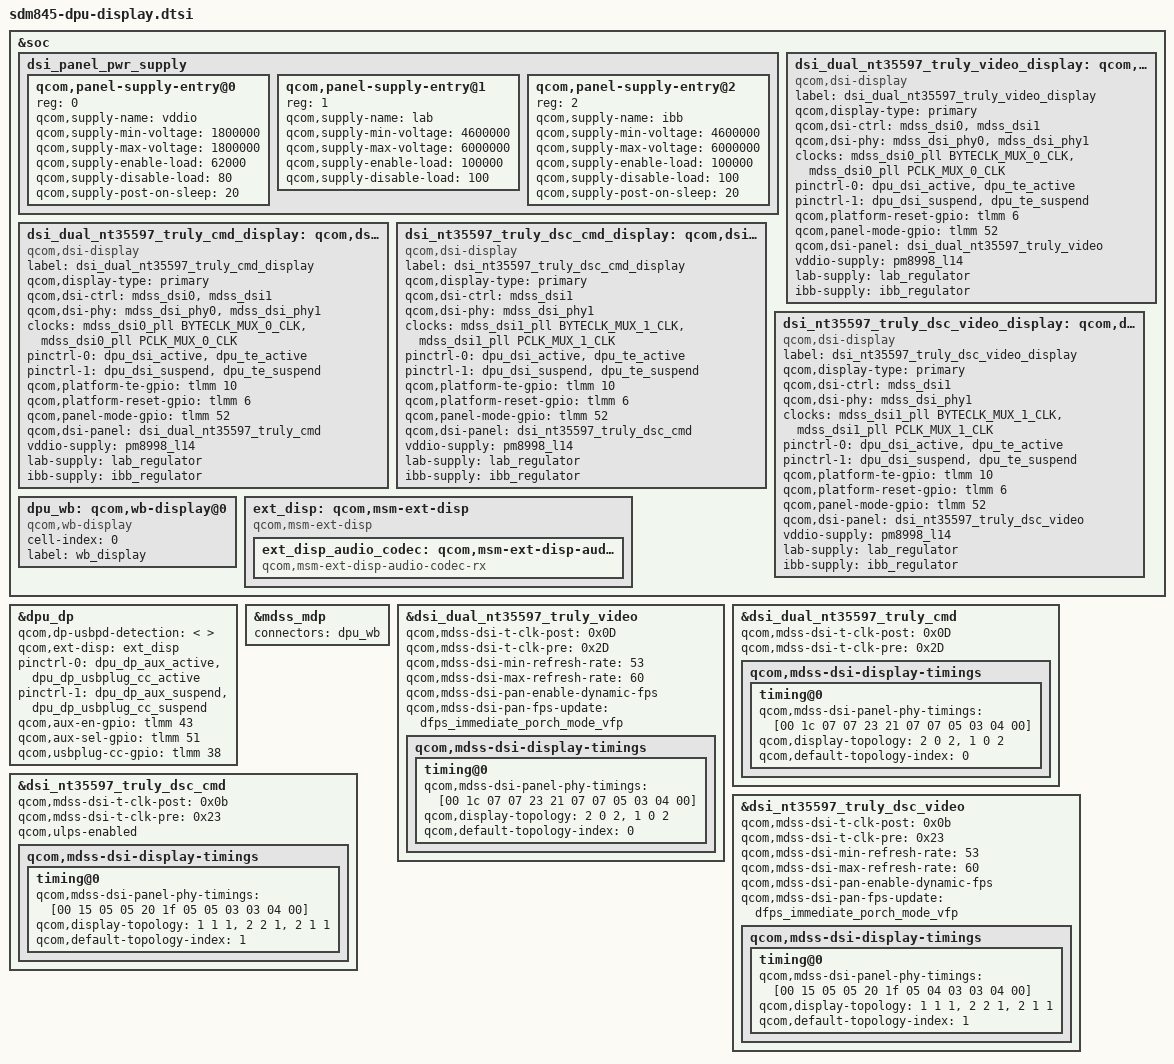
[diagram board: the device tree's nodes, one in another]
/* Copyright (c) 2016-2018, The Linux Foundation. All rights reserved.
 *
 * This program is free software; you can redistribute it and/or modify
 * it under the terms of the GNU General Public License version 2 and
 * only version 2 as published by the Free Software Foundation.
 *
 * This program is distributed in the hope that it will be useful,
 * but WITHOUT ANY WARRANTY; without even the implied warranty of
 * MERCHANTABILITY or FITNESS FOR A PARTICULAR PURPOSE.  See the
 * GNU General Public License for more details.
 */

#include "dsi-panel-nt35597-truly-dualmipi-wqxga-video.dtsi"
#include "dsi-panel-nt35597-truly-dualmipi-wqxga-cmd.dtsi"
#include "dsi-panel-nt35597-truly-dsc-wqxga-cmd.dtsi"
#include "dsi-panel-nt35597-truly-dsc-wqxga-video.dtsi"
#include <dt-bindings/clock/mdss-10nm-pll-clk.h>

&soc {
	dsi_panel_pwr_supply: dsi_panel_pwr_supply {
		#address-cells = <1>;
		#size-cells = <0>;

		qcom,panel-supply-entry@0 {
			reg = <0>;
			qcom,supply-name = "vddio";
			qcom,supply-min-voltage = <1800000>;
			qcom,supply-max-voltage = <1800000>;
			qcom,supply-enable-load = <62000>;
			qcom,supply-disable-load = <80>;
			qcom,supply-post-on-sleep = <20>;
		};

		qcom,panel-supply-entry@1 {
			reg = <1>;
			qcom,supply-name = "lab";
			qcom,supply-min-voltage = <4600000>;
			qcom,supply-max-voltage = <6000000>;
			qcom,supply-enable-load = <100000>;
			qcom,supply-disable-load = <100>;
		};

		qcom,panel-supply-entry@2 {
			reg = <2>;
			qcom,supply-name = "ibb";
			qcom,supply-min-voltage = <4600000>;
			qcom,supply-max-voltage = <6000000>;
			qcom,supply-enable-load = <100000>;
			qcom,supply-disable-load = <100>;
			qcom,supply-post-on-sleep = <20>;
		};
	};

	dsi_dual_nt35597_truly_video_display: qcom,dsi-display@4 {
		compatible = "qcom,dsi-display";
		label = "dsi_dual_nt35597_truly_video_display";
		qcom,display-type = "primary";

		qcom,dsi-ctrl = <&mdss_dsi0 &mdss_dsi1>;
		qcom,dsi-phy = <&mdss_dsi_phy0 &mdss_dsi_phy1>;
		clocks = <&mdss_dsi0_pll BYTECLK_MUX_0_CLK>,
			<&mdss_dsi0_pll PCLK_MUX_0_CLK>;
		clock-names = "src_byte_clk", "src_pixel_clk";

		pinctrl-names = "panel_active", "panel_suspend";
		pinctrl-0 = <&dpu_dsi_active &dpu_te_active>;
		pinctrl-1 = <&dpu_dsi_suspend &dpu_te_suspend>;
		qcom,platform-reset-gpio = <&tlmm 6 0>;
		qcom,panel-mode-gpio = <&tlmm 52 0>;

		qcom,dsi-panel = <&dsi_dual_nt35597_truly_video>;
		vddio-supply = <&pm8998_l14>;
		lab-supply = <&lab_regulator>;
		ibb-supply = <&ibb_regulator>;
	};

	dsi_dual_nt35597_truly_cmd_display: qcom,dsi-display@5 {
		compatible = "qcom,dsi-display";
		label = "dsi_dual_nt35597_truly_cmd_display";
		qcom,display-type = "primary";

		qcom,dsi-ctrl = <&mdss_dsi0 &mdss_dsi1>;
		qcom,dsi-phy = <&mdss_dsi_phy0 &mdss_dsi_phy1>;
		clocks = <&mdss_dsi0_pll BYTECLK_MUX_0_CLK>,
			<&mdss_dsi0_pll PCLK_MUX_0_CLK>;
		clock-names = "src_byte_clk", "src_pixel_clk";

		pinctrl-names = "panel_active", "panel_suspend";
		pinctrl-0 = <&dpu_dsi_active &dpu_te_active>;
		pinctrl-1 = <&dpu_dsi_suspend &dpu_te_suspend>;
		qcom,platform-te-gpio = <&tlmm 10 0>;
		qcom,platform-reset-gpio = <&tlmm 6 0>;
		qcom,panel-mode-gpio = <&tlmm 52 0>;

		qcom,dsi-panel = <&dsi_dual_nt35597_truly_cmd>;
		vddio-supply = <&pm8998_l14>;
		lab-supply = <&lab_regulator>;
		ibb-supply = <&ibb_regulator>;
	};

	dsi_nt35597_truly_dsc_cmd_display: qcom,dsi-display@6 {
		compatible = "qcom,dsi-display";
		label = "dsi_nt35597_truly_dsc_cmd_display";
		qcom,display-type = "primary";

		qcom,dsi-ctrl = <&mdss_dsi1>;
		qcom,dsi-phy = <&mdss_dsi_phy1>;
		clocks = <&mdss_dsi1_pll BYTECLK_MUX_1_CLK>,
			<&mdss_dsi1_pll PCLK_MUX_1_CLK>;
		clock-names = "src_byte_clk", "src_pixel_clk";

		pinctrl-names = "panel_active", "panel_suspend";
		pinctrl-0 = <&dpu_dsi_active &dpu_te_active>;
		pinctrl-1 = <&dpu_dsi_suspend &dpu_te_suspend>;
		qcom,platform-te-gpio = <&tlmm 10 0>;
		qcom,platform-reset-gpio = <&tlmm 6 0>;
		qcom,panel-mode-gpio = <&tlmm 52 0>;

		qcom,dsi-panel = <&dsi_nt35597_truly_dsc_cmd>;
		vddio-supply = <&pm8998_l14>;
		lab-supply = <&lab_regulator>;
		ibb-supply = <&ibb_regulator>;
	};

	dsi_nt35597_truly_dsc_video_display: qcom,dsi-display@7 {
		compatible = "qcom,dsi-display";
		label = "dsi_nt35597_truly_dsc_video_display";
		qcom,display-type = "primary";

		qcom,dsi-ctrl = <&mdss_dsi1>;
		qcom,dsi-phy = <&mdss_dsi_phy1>;
		clocks = <&mdss_dsi1_pll BYTECLK_MUX_1_CLK>,
			<&mdss_dsi1_pll PCLK_MUX_1_CLK>;
		clock-names = "src_byte_clk", "src_pixel_clk";

		pinctrl-names = "panel_active", "panel_suspend";
		pinctrl-0 = <&dpu_dsi_active &dpu_te_active>;
		pinctrl-1 = <&dpu_dsi_suspend &dpu_te_suspend>;
		qcom,platform-te-gpio = <&tlmm 10 0>;
		qcom,platform-reset-gpio = <&tlmm 6 0>;
		qcom,panel-mode-gpio = <&tlmm 52 0>;

		qcom,dsi-panel = <&dsi_nt35597_truly_dsc_video>;
		vddio-supply = <&pm8998_l14>;
		lab-supply = <&lab_regulator>;
		ibb-supply = <&ibb_regulator>;
	};

	dpu_wb: qcom,wb-display@0 {
		compatible = "qcom,wb-display";
		cell-index = <0>;
		label = "wb_display";
	};

	ext_disp: qcom,msm-ext-disp {
		compatible = "qcom,msm-ext-disp";

		ext_disp_audio_codec: qcom,msm-ext-disp-audio-codec-rx {
			compatible = "qcom,msm-ext-disp-audio-codec-rx";
		};
	};
};

&dpu_dp {
	qcom,dp-usbpd-detection = </*&pmi8998_pdphy*/>;
	qcom,ext-disp = <&ext_disp>;

	pinctrl-names = "mdss_dp_active", "mdss_dp_sleep";
	pinctrl-0 = <&dpu_dp_aux_active &dpu_dp_usbplug_cc_active>;
	pinctrl-1 = <&dpu_dp_aux_suspend &dpu_dp_usbplug_cc_suspend>;
	qcom,aux-en-gpio = <&tlmm 43 0>;
	qcom,aux-sel-gpio = <&tlmm 51 0>;
	qcom,usbplug-cc-gpio = <&tlmm 38 0>;
};

&mdss_mdp {
	connectors = <&dpu_wb>;
};

&dsi_dual_nt35597_truly_video {
	qcom,mdss-dsi-t-clk-post = <0x0D>;
	qcom,mdss-dsi-t-clk-pre = <0x2D>;
	qcom,mdss-dsi-min-refresh-rate = <53>;
	qcom,mdss-dsi-max-refresh-rate = <60>;
	qcom,mdss-dsi-pan-enable-dynamic-fps;
	qcom,mdss-dsi-pan-fps-update =
		"dfps_immediate_porch_mode_vfp";
	qcom,mdss-dsi-display-timings {
		timing@0{
			qcom,mdss-dsi-panel-phy-timings = [00 1c 07 07 23 21 07
				07 05 03 04 00];
			qcom,display-topology = <2 0 2>,
						<1 0 2>;
			qcom,default-topology-index = <0>;
		};
	};
};

&dsi_dual_nt35597_truly_cmd {
	qcom,mdss-dsi-t-clk-post = <0x0D>;
	qcom,mdss-dsi-t-clk-pre = <0x2D>;
	qcom,mdss-dsi-display-timings {
		timing@0{
			qcom,mdss-dsi-panel-phy-timings = [00 1c 07 07 23 21 07
				07 05 03 04 00];
			qcom,display-topology = <2 0 2>,
						<1 0 2>;
			qcom,default-topology-index = <0>;
		};
	};
};

&dsi_nt35597_truly_dsc_cmd {
	qcom,mdss-dsi-t-clk-post = <0x0b>;
	qcom,mdss-dsi-t-clk-pre = <0x23>;
	qcom,ulps-enabled;
	qcom,mdss-dsi-display-timings {
		timing@0{
			qcom,mdss-dsi-panel-phy-timings = [00 15 05 05 20 1f 05
				05 03 03 04 00];
			qcom,display-topology = <1 1 1>,
						<2 2 1>, /* dsc merge */
						<2 1 1>; /* 3d mux */
			qcom,default-topology-index = <1>;
		};
	};
};

&dsi_nt35597_truly_dsc_video {
	qcom,mdss-dsi-t-clk-post = <0x0b>;
	qcom,mdss-dsi-t-clk-pre = <0x23>;
	qcom,mdss-dsi-min-refresh-rate = <53>;
	qcom,mdss-dsi-max-refresh-rate = <60>;
	qcom,mdss-dsi-pan-enable-dynamic-fps;
	qcom,mdss-dsi-pan-fps-update =
		"dfps_immediate_porch_mode_vfp";
	qcom,mdss-dsi-display-timings {
		timing@0{
			qcom,mdss-dsi-panel-phy-timings = [00 15 05 05 20 1f 05
				04 03 03 04 00];
			qcom,display-topology = <1 1 1>,
						<2 2 1>, /* dsc merge */
						<2 1 1>; /* 3d mux */
			qcom,default-topology-index = <1>;
		};
	};
};

